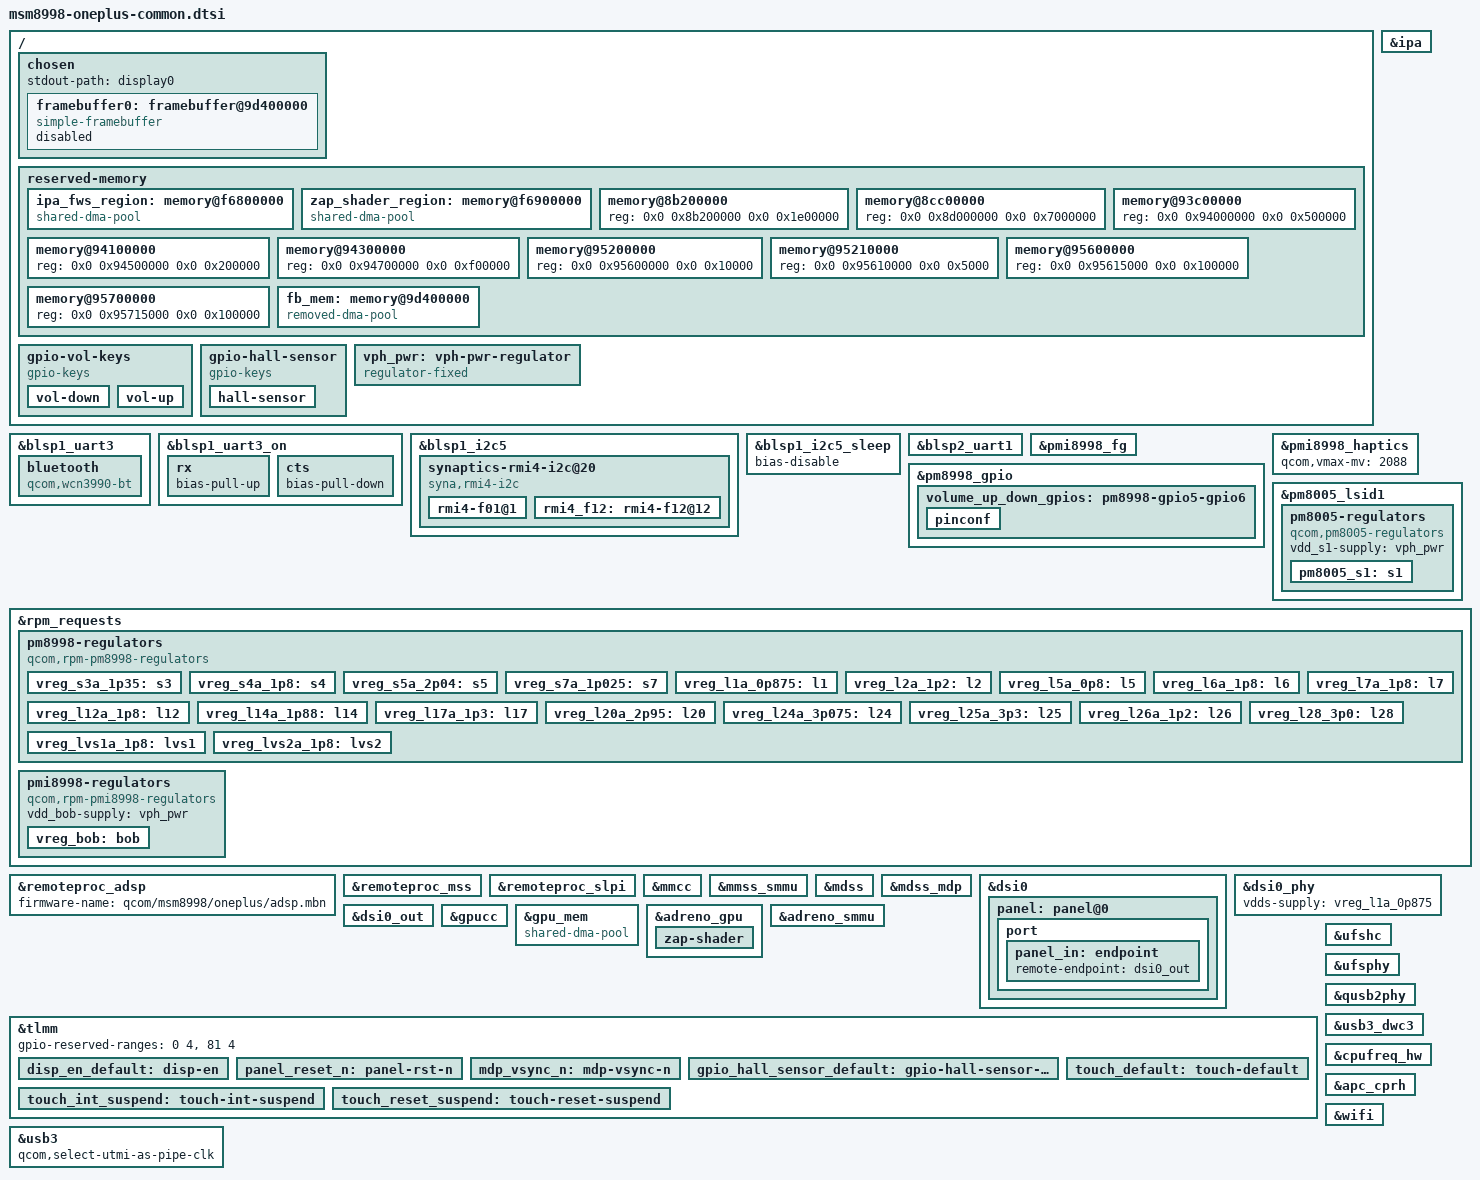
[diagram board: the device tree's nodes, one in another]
// SPDX-License-Identifier: GPL-2.0-only
/*
 * OnePlus 5(T) (cheeseburger / dumpling) common device tree source
 *
 * Copyright (c) 2021, The Linux Foundation. All rights reserved.
 */

/dts-v1/;

#include <dt-bindings/gpio/gpio.h>
#include <dt-bindings/pinctrl/qcom,pmic-gpio.h>
#include "msm8998.dtsi"
#include "pm8998.dtsi"
#include "pmi8998.dtsi"
#include "pm8005.dtsi"

/ {
	chosen {
		#address-cells = <2>;
		#size-cells = <2>;
		ranges;

		stdout-path = "display0";

		/* Use display framebuffer setup by the UEFI XBL bootloader for simplefb. */
		framebuffer0: framebuffer@9d400000 {
			compatible = "simple-framebuffer";
			reg = <0 0x9d400000 0 (1080 * 1920 * 4)>;
			width = <1080>;
			height = <1920>;
			stride = <(1080 * 4)>;
			format = "a8r8g8b8";
			status = "disabled";
		};
	};

	reserved-memory {
		/* Allocate these as seen on downstream */
		ipa_fws_region: memory@f6800000 {
			compatible = "shared-dma-pool";
			reg = <0x0 0xf6800000 0x0 0x5000>; // 20 KiB
			no-map;
		};

		zap_shader_region: memory@f6900000 {
			compatible = "shared-dma-pool";
			reg = <0x0 0xf6900000 0x0 0x2000>; // 8 KiB
			no-map;
		};

		/*
		 * OnePlus' adsp.mbn firmware requires 30 MiB in total, so increase the adsp_mem
		 * region by 4 MiB to account for this and relocate other now conflicting memory
		 * nodes accordingly.
		 */
		memory@8b200000 {         /* adsp_mem */
			reg = <0x0 0x8b200000 0x0 0x1e00000>;
		};

		memory@8cc00000 {         /* mpss_mem */
			reg = <0x0 0x8d000000 0x0 0x7000000>;
		};
		memory@93c00000 {         /* venus_mem */
			reg = <0x0 0x94000000 0x0 0x500000>;
		};
		memory@94100000 {         /* mba_mem */
			reg = <0x0 0x94500000 0x0 0x200000>;
		};
		memory@94300000 {         /* slpi_mem */
			reg = <0x0 0x94700000 0x0 0xf00000>;
		};
		memory@95200000 {         /* ipa_fw_mem */
			reg = <0x0 0x95600000 0x0 0x10000>;
		};
		memory@95210000 {         /* ipa_gsi_mem */
			reg = <0x0 0x95610000 0x0 0x5000>;
		};
		memory@95600000 {         /* gpu_mem */
			reg = <0x0 0x95615000 0x0 0x100000>;
		};
		memory@95700000 {         /* wlan_msa_mem */
			reg = <0x0 0x95715000 0x0 0x100000>;
		};

		/* Bootloader display framebuffer region */
		fb_mem: memory@9d400000 {
			compatible = "removed-dma-pool";
			reg = <0 0x9d400000 0 (1080 * 1920 * 4)>;
			no-map;
		};
	};

	gpio-vol-keys {
		compatible = "gpio-keys";
		label = "Volume keys";
		//autorepeat;

		pinctrl-names = "default";
		pinctrl-0 = <&volume_up_down_gpios>;

		vol-down {
			label = "Volume down";
			linux,code = <KEY_VOLUMEDOWN>;
			gpios = <&pm8998_gpio 5 GPIO_ACTIVE_LOW>;
			debounce-interval = <15>;
		};

		vol-up {
			label = "Volume up";
			linux,code = <KEY_VOLUMEUP>;
			gpios = <&pm8998_gpio 6 GPIO_ACTIVE_LOW>;
			debounce-interval = <15>;
		};
	};

	gpio-hall-sensor {
		compatible = "gpio-keys";
		label = "Hall effect sensor";

		pinctrl-names = "default";
		pinctrl-0 = <&gpio_hall_sensor_default>;

		hall-sensor {
			label = "Hall Effect Sensor";
			linux,input-type = <EV_SW>;
			linux,code = <SW_LID>;
			linux,can-disable;
			gpios = <&tlmm 124 GPIO_ACTIVE_LOW>;
		};
	};

	vph_pwr: vph-pwr-regulator {
		compatible = "regulator-fixed";
		regulator-name = "vph_pwr";
		regulator-always-on;
		regulator-boot-on;
	};
};

&blsp1_uart3 {
	status = "okay";

	bluetooth {
		compatible = "qcom,wcn3990-bt";

		vddio-supply = <&vreg_s4a_1p8>;
		vddxo-supply = <&vreg_l7a_1p8>;
		vddrf-supply = <&vreg_l17a_1p3>;
		vddch0-supply = <&vreg_l25a_3p3>;
		max-speed = <3200000>;
	};
};

&blsp1_uart3_on {
	rx {
		/delete-property/ bias-disable;
		/*
		 * Configure a pull-up on 45 (RX). This is needed to
		 * avoid garbage data when the TX pin of the Bluetooth
		 * module is in tri-state (module powered off or not
		 * driving the signal yet).
		 */
		bias-pull-up;
	};

	cts {
		/delete-property/ bias-disable;
		/*
		 * Configure a pull-down on 47 (CTS) to match the pull
		 * of the Bluetooth module.
		 */
		bias-pull-down;
	};
};

&blsp1_i2c5 {
	pinctrl-names = "default", "sleep";
	pinctrl-0 = <&blsp1_i2c5_default>;
	pinctrl-1 = <&blsp1_i2c5_sleep>;
	status = "okay";

	synaptics-rmi4-i2c@20 {
		compatible = "syna,rmi4-i2c";
		reg = <0x20>;
		#address-cells = <1>;
		#size-cells = <0>;
		interrupts-extended = <&tlmm 125 IRQ_TYPE_EDGE_FALLING>;

		pinctrl-names = "default", "sleep";
		pinctrl-0 = <&touch_default>;
		pinctrl-1 = <&touch_int_suspend &touch_reset_suspend>;

		vdd-supply = <&vreg_l28_3p0>;
		vio-supply = <&vreg_l6a_1p8>;

		syna,reset-delay-ms = <200>;
		syna,startup-delay-ms = <200>;

		rmi4-f01@1 {
			reg = <0x01>;
			syna,nosleep-mode = <1>;
		};

		rmi4_f12: rmi4-f12@12 {
			reg = <0x12>;
			touchscreen-x-mm = <68>;
			touchscreen-y-mm = <122>;
			syna,sensor-type = <1>;
			syna,rezero-wait-ms = <200>;
		};
	};
};

&blsp1_i2c5_sleep {
	/delete-property/ bias-pull-up;
	/* Configure a no-pull on TP I2C sleep to match downstream. */
	bias-disable;
};

&blsp2_uart1 {
	status = "okay";
};

&ipa {
	status = "okay";

	memory-region = <&ipa_fws_region>; // ipa_fw_mem
	firmware-name = "qcom/msm8998/oneplus/ipa_fws.mbn";
};

&pmi8998_fg {
	status = "okay";

	qcom,max-voltage-uv = <4370000>;
	qcom,min-voltage-uv = <3700000>;
	qcom,battery-capacity-ua = <3300000>;
};

&pm8998_gpio {
	volume_up_down_gpios: pm8998-gpio5-gpio6 {
		pinconf {
			pins = "gpio5", "gpio6";
			function = "normal";
			input-enable;
			bias-pull-up;
			qcom,drive-strength = <PMIC_GPIO_STRENGTH_NO>;
		};
	};
};

&pmi8998_haptics {
	status = "okay";

	qcom,vmax-mv = <2088>; // 3596 for SDM845?

	//qcom,brake-pattern = <0x3030303>;

	//qcom,int-pwm-freq-khz = <0x1f9>; // 505
	//qcom,sc-deb-cycles = <0x08>; // 8
	//qcom,correct-lra-drive-freq;
	//qcom,wave-samples = <0x28282828 0x28282828>;
	//qcom,wave-samples-overdrive = <0x7e7e7e7e 0x7e282828>;
	//qcom,use-play-irq;
};

&pm8005_lsid1 {
	pm8005-regulators {
		compatible = "qcom,pm8005-regulators";

		vdd_s1-supply = <&vph_pwr>;

		pm8005_s1: s1 { /* VDD_GFX supply */
			regulator-min-microvolt = <524000>;
			regulator-max-microvolt = <1100000>;
			regulator-enable-ramp-delay = <500>;

			/* hack until we rig up the gpu consumer */
			regulator-always-on;
		};
	};
};

&rpm_requests {
	pm8998-regulators {
		compatible = "qcom,rpm-pm8998-regulators";

		vdd_s1-supply = <&vph_pwr>; /* GPU? */
		vdd_s3-supply = <&vph_pwr>;
		vdd_s4-supply = <&vph_pwr>;
		vdd_s5-supply = <&vph_pwr>;
		vdd_s7-supply = <&vph_pwr>;
		vdd_l1-supply = <&vreg_s7a_1p025>;
		vdd_l2_l17-supply = <&vreg_s3a_1p35>;
		vdd_l5-supply = <&vreg_s7a_1p025>;
		vdd_l6-supply = <&vreg_s5a_2p04>;
		vdd_l7_l12_l14-supply = <&vreg_s5a_2p04>;
		vdd_l25-supply = <&vreg_bob>;
		vdd_l28-supply = <&vreg_bob>;
		vdd_l20_l24-supply = <&vreg_bob>;
		vdd_l26-supply = <&vreg_s3a_1p35>;
		vdd_lvs1_lvs2-supply = <&vreg_s4a_1p8>;

		vreg_s3a_1p35: s3 {
			regulator-min-microvolt = <1352000>;
			regulator-max-microvolt = <1352000>;
		};
		vreg_s4a_1p8: s4 {
			regulator-min-microvolt = <1800000>;
			regulator-max-microvolt = <1800000>;
			regulator-allow-set-load;
		};
		vreg_s5a_2p04: s5 {
			regulator-min-microvolt = <1904000>;
			regulator-max-microvolt = <2040000>;
		};
		vreg_s7a_1p025: s7 {
			regulator-min-microvolt = <900000>;
			regulator-max-microvolt = <1028000>;
		};
		vreg_l1a_0p875: l1 { /* UFS PHY */
			regulator-min-microvolt = <880000>;
			regulator-max-microvolt = <880000>;
		};
		vreg_l2a_1p2: l2 { /* UFS PHY */
			regulator-min-microvolt = <1200000>;
			regulator-max-microvolt = <1200000>;
		};
		vreg_l5a_0p8: l5 { /* Wi-Fi */
			regulator-min-microvolt = <800000>;
			regulator-max-microvolt = <800000>;
		};
		vreg_l6a_1p8: l6 { /* Touchscreen */
			regulator-min-microvolt = <1808000>;
			regulator-max-microvolt = <1808000>;
		};
		vreg_l7a_1p8: l7 { /* Wi-Fi + BT */
			regulator-min-microvolt = <1800000>;
			regulator-max-microvolt = <1800000>;
		};
		vreg_l12a_1p8: l12 { /* QUSB2 PHY */
			regulator-min-microvolt = <1800000>;
			regulator-max-microvolt = <1800000>;
		};
		vreg_l14a_1p88: l14 { /* DSI display */
			regulator-min-microvolt = <1880000>;
			regulator-max-microvolt = <1880000>;
		};
		vreg_l17a_1p3: l17 { /* Wi-Fi + BT */
			regulator-min-microvolt = <1304000>;
			regulator-max-microvolt = <1304000>;
		};
		vreg_l20a_2p95: l20 { /* UFS HC */
			regulator-min-microvolt = <2960000>;
			regulator-max-microvolt = <2960000>;
			regulator-allow-set-load;
		};
		vreg_l24a_3p075: l24 { /* QUSB2 PHY */
			regulator-min-microvolt = <3088000>;
			regulator-max-microvolt = <3088000>;
		};
		vreg_l25a_3p3: l25 { /* Wi-Fi + BT */
			regulator-min-microvolt = <3104000>;
			regulator-max-microvolt = <3312000>;
		};
		vreg_l26a_1p2: l26 { /* UFS PHY + HC */
			regulator-min-microvolt = <1200000>;
			regulator-max-microvolt = <1200000>;
			regulator-allow-set-load;
		};
		vreg_l28_3p0: l28 { /* Touchscreen */
			regulator-min-microvolt = <3008000>;
			regulator-max-microvolt = <3008000>;
		};
		vreg_lvs1a_1p8: lvs1 { };
		vreg_lvs2a_1p8: lvs2 { };
	};

	pmi8998-regulators {
		compatible = "qcom,rpm-pmi8998-regulators";

		vdd_bob-supply = <&vph_pwr>;

		vreg_bob: bob {
			regulator-min-microvolt = <3312000>;
			regulator-max-microvolt = <3600000>;
		};
	};
};

&remoteproc_adsp {
	status = "okay";

	firmware-name = "qcom/msm8998/oneplus/adsp.mbn";
};

&remoteproc_mss {
	firmware-name = "qcom/msm8998/oneplus/mba.mbn", "qcom/msm8998/oneplus/modem.mbn";
};

&remoteproc_slpi {
	status = "okay";

	firmware-name = "qcom/msm8998/oneplus/slpi_v2.mbn";
};

&mmcc {
	status = "okay";
};

&mmss_smmu {
	status = "okay";
};

&mdss {
	status = "okay";
};

&mdss_mdp {
	status = "okay";
};

&dsi0 {
	#address-cells = <1>;
	#size-cells = <0>;
	status = "okay";

	// TODO: Double-check that both 5/5T models use these!
	vdd-supply = <&vreg_l1a_0p875>;
	vdda-supply = <&vreg_l2a_1p2>;

	panel: panel@0 {
		reg = <0>;

		reset-gpios = <&tlmm 94 GPIO_ACTIVE_LOW>;
		disp-te-gpios = <&tlmm 11 GPIO_ACTIVE_LOW>;

		vddio-supply = <&vreg_l14a_1p88>; // TODO: Could this be moved under dsi0?

		// TODO: Double-check that both 5/5T models use these!
		pinctrl-names = "default";
		pinctrl-0 = <&panel_reset_n &disp_en_default &mdp_vsync_n>;

		port {
			panel_in: endpoint {
				remote-endpoint = <&dsi0_out>;
			};
		};
	};
};

&dsi0_phy {
	status = "okay";
	vdds-supply = <&vreg_l1a_0p875>;
};

&dsi0_out {
	remote-endpoint = <&panel_in>;
	data-lanes = <0 1 2 3>;
};

/* Adreno 540 GPU */
&gpucc {
	status = "ok";
};

&gpu_mem {
	compatible = "shared-dma-pool";
};

&adreno_gpu {
	status = "ok";

	zap-shader {
		memory-region = <&zap_shader_region>; // gpu_mem
		firmware-name = "qcom/a540_zap.mbn";
	};
};

&adreno_smmu {
	status = "ok";
};

/*
 * HACK: Shoot GPU voltage high to stabilize Adreno 540 at high frequencies
 *       until the GPU CPR is brought up.
 */
&pm8005_s1 {
	regulator-min-microvolt = <988000>; /* 0,524V -> 0,988V */
	//regulator-max-microvolt = <1100000>;
};

&tlmm {
	gpio-reserved-ranges = <0 4>, <81 4>;

	// TODO: Double-check that both 5/5T models use these (disp_en_default, panel_reset_n, mdp_vsync_n)!
	disp_en_default: disp-en {
		pins = "gpio62"; // TODO: Add "gpio66" for 5T as well!
		function = "gpio";
		drive-strength = <8>;
		bias-disable;
	};

	panel_reset_n: panel-rst-n {
		pins = "gpio94";
		function = "gpio";
		drive-strength = <8>;
		bias-disable;
	};

	mdp_vsync_n: mdp-vsync-n {
		pins = "gpio11";
		function = "mdp_vsync_a";
		drive-strength = <2>;
		bias-pull-down;
	};

	gpio_hall_sensor_default: gpio-hall-sensor-default {
		pins = "gpio124";
		function = "gpio";
		drive-strength = <2>;
		bias-disable;
		input-enable;
	};

	touch_default: touch-default {
		pins = "gpio89", "gpio125";
		function = "gpio";
		drive-strength = <16>;
		bias-pull-up;
	};

	touch_int_suspend: touch-int-suspend {
		pins = "gpio125";
		function = "gpio";
		drive-strength = <2>;
		bias-disable;
	};

	touch_reset_suspend: touch-reset-suspend {
		pins = "gpio89";
		function = "gpio";
		drive-strength = <2>;
		bias-pull-down;
	};
};

&ufshc {
	status = "okay";

	vcc-supply = <&vreg_l20a_2p95>;
	vccq-supply = <&vreg_l26a_1p2>;
	vccq2-supply = <&vreg_s4a_1p8>;
	//vdd-hba-supply = <&vreg_???>; // TODO: (UFS host controller supply regulator node)
	vcc-max-microamp = <750000>;
	vccq-max-microamp = <560000>;
	vccq2-max-microamp = <750000>;
};

&ufsphy {
	status = "okay";

	vdda-phy-supply = <&vreg_l1a_0p875>;
	vdda-pll-supply = <&vreg_l2a_1p2>;
	vddp-ref-clk-supply = <&vreg_l26a_1p2>;
	vdda-phy-max-microamp = <51400>;
	vdda-pll-max-microamp = <14600>;
	vddp-ref-clk-max-microamp = <100>;
	vddp-ref-clk-always-on;
};

&qusb2phy {
	status = "okay";

	vdda-pll-supply = <&vreg_l12a_1p8>;
	vdda-phy-dpdm-supply = <&vreg_l24a_3p075>;
};

&usb3 {
	status = "okay";

	qcom,select-utmi-as-pipe-clk; /* Disable USB 3 pipe_clk requirement */
};

&usb3_dwc3 {
	/* Drop the unused USB 3 SuperSpeed PHY */
	phys = <&qusb2phy>;
	phy-names = "usb2-phy";

	maximum-speed = "high-speed"; /* We can only operate at USB 2.0 speeds */
	
	dr_mode = "peripheral"; /* Force to peripheral until we have the capability to switch modes */
};

&cpufreq_hw {
	status = "ok";
};

&apc_cprh {
	status = "ok";
};

&wifi {
	status = "okay";

	vdd-0.8-cx-mx-supply = <&vreg_l5a_0p8>;
	vdd-1.8-xo-supply = <&vreg_l7a_1p8>;
	vdd-1.3-rfa-supply = <&vreg_l17a_1p3>;
	vdd-3.3-ch0-supply = <&vreg_l25a_3p3>;
	//vdd-3.3-ch1-supply = <&vreg_???>; // TODO:
};
